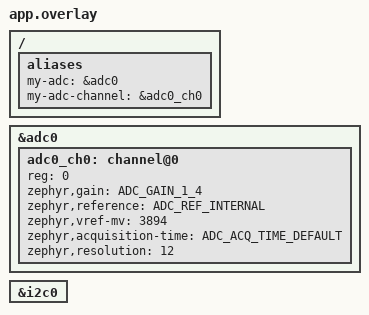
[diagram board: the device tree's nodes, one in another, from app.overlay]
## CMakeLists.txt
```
# SPDX-License-Identifier: Apache-2.0

cmake_minimum_required(VERSION 3.20.0)

find_package(Zephyr REQUIRED HINTS $ENV{ZEPHYR_BASE})
project(display_driver)

target_sources(app PRIVATE src/main.c)
```

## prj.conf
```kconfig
# nothing here
#
CONFIG_I2C=y
CONFIG_I2C_ESP32=y
CONFIG_I2C_TARGET=y
CONFIG_I2C_LOG_LEVEL_DBG=y
CONFIG_LOG=y
```

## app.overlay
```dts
/{
    aliases {
        my-adc = &adc0;
        my-adc-channel = &adc0_ch0;
    };
};

// ADC1 (adc0) channel 0 is connected to GPIO1
&adc0 {
    status = "okay";
    #address-cells = <1>;
    #size-cells = <0>;

    adc0_ch0: channel@0 {
        reg = <0>;
        zephyr,gain = "ADC_GAIN_1_4";
        zephyr,reference = "ADC_REF_INTERNAL";
        zephyr,vref-mv = <3894>;
        zephyr,acquisition-time = <ADC_ACQ_TIME_DEFAULT>;
        zephyr,resolution = <12>;
    };
};

&i2c0 {
    status = "okay";
};
```

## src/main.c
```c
#include <zephyr/device.h>
#include <zephyr/drivers/i2c.h>
#include <zephyr/kernel.h>
#include <zephyr/sys/printk.h>

static const struct device *bus = DEVICE_DT_GET(DT_NODELABEL(i2c0));

// LCD Commands
#define LCD_CLEAR_DISPLAY 0x01
#define LCD_RETURN_HOME 0x02
#define LCD_ENTRY_MODE_SET 0x04
#define LCD_DISPLAY_CONTROL 0x08
#define LCD_FUNCTION_SET 0x20
#define LCD_SET_DDRAM_ADDR 0x80

// Delays
#define LCD_POWER_ON_DELAY_MS 50
#define LCD_INIT_DELAY_US 100
#define LCD_CMD_DELAY_US 37
void debug_bin(uint8_t number) {
    char number_str[9];  // 8 bits + null terminator
    printk("The original number is %d\n", number);
    
    for (int i = 0; i < 8; i++) {
        uint8_t bit = (number >> (7 - i)) & 0b00000001;  // Start with MSB
        number_str[i] = bit ? '1' : '0';
    }
    number_str[8] = '\0';  // Null-terminate the string
    
    printk("The binary representation is: %s\n", number_str);
}
void send_data_half(const struct device *dev, uint8_t data, uint8_t addr,
                    uint8_t rs) {
  // uint8_t buffer;
  printk("sending command:\n");
  // High nibble + RS + Backlight ON (0x08)
  // buffer = (data & 0xF0) | (rs ? 0x01 : 0x00) | 0x08;
  uint8_t buffer[4] = {(data & 0xF0) | (rs ? 0x0d : 0x0c),
                       (data & 0xF0) | (rs ? 0x09 : 0x08),
                       ((data << 4) & 0xF0) | (rs ? 0x0d : 0x0c),
                       ((data << 4) & 0xF0) | (rs ? 0x09 : 0x08)};
  // Pulse EN (set high then low)
  for(int i = 0; i < 4; i++){
        debug_bin(buffer[i]);
    }
  i2c_write(dev, &buffer, sizeof(buffer), addr); // EN=1
  k_usleep(LCD_CMD_DELAY_US);
}

void init_my_lcd(const struct device *i2c_dev, uint8_t addr) {
  k_msleep(LCD_POWER_ON_DELAY_MS);

  // Initialization sequence
  send_data_half(i2c_dev, 0x33, addr, 0);
  k_msleep(50);
  send_data_half(i2c_dev, 0x32, addr, 0);
   k_msleep(50);
  send_data_half(i2c_dev, LCD_FUNCTION_SET | 0x08, addr, 0);
  k_msleep(50);
  send_data_half(i2c_dev, LCD_DISPLAY_CONTROL | 0x04, addr, 0);
  k_msleep(50);
  send_data_half(i2c_dev, LCD_CLEAR_DISPLAY, addr, 0);
  k_msleep(50);
  send_data_half(i2c_dev, LCD_ENTRY_MODE_SET | 0x02, addr, 0);
  k_msleep(2);
}

void send_string(const struct device *dev,uint8_t addr, char *string, int str_length){
  for(int i = 0; i < str_length; i++)
  {
    send_data_half(dev, string[i], addr,1);
    k_msleep(2);
  }
}
int main(void) {
  const struct device *i2c_dev = DEVICE_DT_GET(DT_NODELABEL(i2c0));
  uint8_t lcd_addr = 0x3F; // Try 0x27 if this doesn't work

  if (!device_is_ready(i2c_dev)) {
    printk("I2C device not ready\n");
    return -1;
  }
  init_my_lcd(i2c_dev, lcd_addr);
  // Set cursor to first line beginning
  send_data_half(i2c_dev, 0x80, lcd_addr, 0);
  k_msleep(5);
  char msg[12] = "LKCasa teste";
  send_string(i2c_dev, lcd_addr, msg, 12);
  
  // Set cursor to second line beginning
   send_data_half(i2c_dev, 0x0f, lcd_addr,0);
  return 0;
}
```

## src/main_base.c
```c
#include <zephyr/kernel.h>
#include <zephyr/device.h>
#include <zephyr/drivers/i2c.h>

#define LCD_ADDR 0x3f
#define LCD_CLEAR 0x01
#define LCD_HOME 0x02
#define LCD_ENTRY_MODE 0x04
#define LCD_DISPLAY_CTRL 0x08
#define LCD_FUNCTION_SET 0x20

void lcd_send_cmd(const struct device *i2c_dev, uint8_t cmd)
{
    uint8_t data[4] = {
        (cmd & 0xF0) | 0x04, // High nibble + EN=1, RS=0
        (cmd & 0xF0) | 0x00, // High nibble + EN=0, RS=0
        ((cmd << 4) & 0xF0) | 0x04, // Low nibble + EN=1, RS=0
        ((cmd << 4) & 0xF0) | 0x00  // Low nibble + EN=0, RS=0
    };
    i2c_write(i2c_dev, data, sizeof(data), LCD_ADDR);
}

void lcd_send_data(const struct device *i2c_dev, uint8_t data)
{
    uint8_t buf[4] = {
        (data & 0xF0) | 0x05, // High nibble + EN=1, RS=1
        (data & 0xF0) | 0x01, // High nibble + EN=0, RS=1
        ((data << 4) & 0xF0) | 0x05, // Low nibble + EN=1, RS=1
        ((data << 4) & 0xF0) | 0x01  // Low nibble + EN=0, RS=1
    };
    i2c_write(i2c_dev, buf, sizeof(buf), LCD_ADDR);
}

void lcd_init(const struct device *i2c_dev)
{
    k_msleep(50);
    
    // Initialization sequence
    lcd_send_cmd(i2c_dev, 0x33);
    lcd_send_cmd(i2c_dev, 0x32);
    lcd_send_cmd(i2c_dev, LCD_FUNCTION_SET | 0x08); // 2 lines, 5x8 dots
    lcd_send_cmd(i2c_dev, LCD_DISPLAY_CTRL | 0x04); // Display on
    lcd_send_cmd(i2c_dev, LCD_CLEAR);
    lcd_send_cmd(i2c_dev, LCD_ENTRY_MODE | 0x02); // Increment cursor
    k_msleep(2);
}

int main(void)
{
    const struct device *i2c_dev = DEVICE_DT_GET(DT_NODELABEL(i2c0));
    
    if (!device_is_ready(i2c_dev)) {
        printk("I2C device not ready\n");
        return -1;
    }

    lcd_init(i2c_dev);
    
    while (1) {
        printk(" send message hello zephyr");
        lcd_send_cmd(i2c_dev, 0x80); // Move to first line
        const char *line1 = "Hello Zephyr!";
        for (int i = 0; i < strlen(line1); i++) {
            lcd_send_data(i2c_dev, line1[i]);
        }
        printk("send message i2c lcd test");
        lcd_send_cmd(i2c_dev, 0xC0); // Move to second line
        const char *line2 = "I2C LCD Test";
        for (int i = 0; i < strlen(line2); i++) {
            lcd_send_data(i2c_dev, line2[i]);
        }
        
        k_msleep(1000);
    }
    return 0;
}
```
